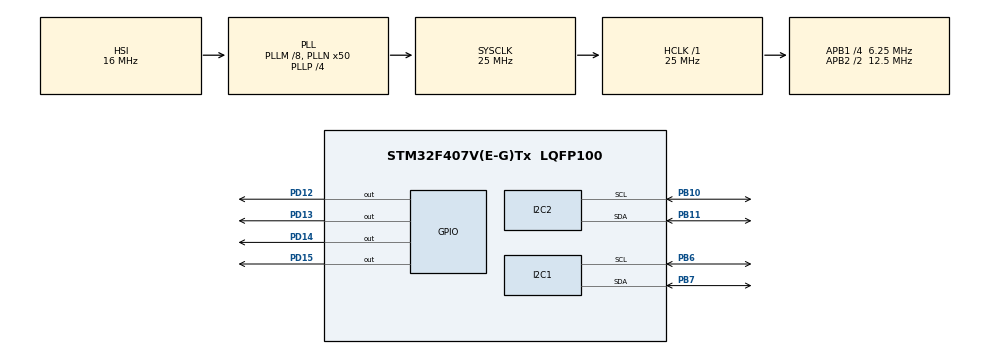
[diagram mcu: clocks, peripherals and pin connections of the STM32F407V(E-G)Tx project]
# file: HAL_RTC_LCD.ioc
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Mcu.Family=STM32F4
Mcu.Name=STM32F407V(E-G)Tx
Mcu.Package=LQFP100
NVIC.PriorityGroup=NVIC_PRIORITYGROUP_0
PB10.Mode=I2C
PB10.Signal=I2C2_SCL
PB11.Mode=I2C
PB11.Signal=I2C2_SDA
PB6.Mode=I2C
PB6.Signal=I2C1_SCL
PB7.Mode=I2C
PB7.Signal=I2C1_SDA
PD12.Signal=GPIO_Output
PD13.Signal=GPIO_Output
PD14.Signal=GPIO_Output
PD15.Signal=GPIO_Output
ProjectManager.HeapSize=0x200
ProjectManager.StackSize=0x400
ProjectManager.TargetToolchain=STM32CubeIDE
RCC.48MHZClocksFreq_Value=14285714.285714285
RCC.AHBFreq_Value=25000000
RCC.APB1CLKDivider=RCC_HCLK_DIV4
RCC.APB1Freq_Value=6250000
RCC.APB1TimFreq_Value=12500000
RCC.APB2CLKDivider=RCC_HCLK_DIV2
RCC.APB2Freq_Value=12500000
RCC.APB2TimFreq_Value=25000000
RCC.CortexFreq_Value=25000000
RCC.HCLKFreq_Value=25000000
RCC.HSE_VALUE=8000000
RCC.HSI_VALUE=16000000
RCC.LSE_VALUE=32768
RCC.PLLM=8
RCC.PLLN=50
RCC.PLLP=RCC_PLLP_DIV4
RCC.PLLQ=7
RCC.SYSCLKFreq_VALUE=25000000
RCC.SYSCLKSource=RCC_SYSCLKSOURCE_PLLCLK
RCC.VCOOutputFreq_Value=100000000
RTC.AsynchPrediv=124
RTC.Date=30
RTC.Format=RTC_FORMAT_BIN
RTC.Hours=23
RTC.Minutes=59
RTC.Month=RTC_MONTH_MARCH
RTC.Seconds=59
RTC.WeekDay=RTC_WEEKDAY_WEDNESDAY
RTC.Year=26
VP_RTC_VS_RTC_Activate.Mode=RTC_Enabled
VP_RTC_VS_RTC_Calendar.Mode=RTC_Calendar
board=STM32F407G-DISC1

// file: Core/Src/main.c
/* USER CODE BEGIN Header */
/**
  ******************************************************************************
  * @file           : main.c
  * @brief          : Main program body
  ******************************************************************************
  * @attention
  *
  * Copyright (c) 2026 STMicroelectronics.
  * All rights reserved.
  *
  * This software is licensed under terms that can be found in the LICENSE file
  * in the root directory of this software component.
  * If no LICENSE file comes with this software, it is provided AS-IS.
  *
  ******************************************************************************
  */
/* USER CODE END Header */
#include "main.h"

/* USER CODE BEGIN Includes */
#include "lcd.h"
#include <stdio.h>
#include <string.h>
/* USER CODE END Includes */

I2C_HandleTypeDef hi2c1;
I2C_HandleTypeDef hi2c2;

RTC_HandleTypeDef hrtc;

void SystemClock_Config(void);
static void MX_GPIO_Init(void);
static void MX_I2C1_Init(void);
static void MX_RTC_Init(void);
static void MX_I2C2_Init(void);

int main(void)
{

  /* MCU Configuration--------------------------------------------------------*/

  /* Reset of all peripherals, Initializes the Flash interface and the Systick. */
  HAL_Init();

  /* Configure the system clock */
  SystemClock_Config();

  /* Initialize all configured peripherals */
  MX_GPIO_Init();
  MX_I2C1_Init();
  MX_RTC_Init();
  MX_I2C2_Init();
  /* USER CODE BEGIN 2 */
  lcd_init();
  lcd_puts(LCD_LINE1, "Hello Kunal");
  char str1[20], str2[20];
  /* USER CODE END 2 */

  /* Infinite loop */
  /* USER CODE BEGIN WHILE */
  while (1)
  {
	  //Get time from rtc
	  RTC_TimeTypeDef time;
	  RTC_DateTypeDef date;
	  HAL_RTC_GetTime(&hrtc, &time, RTC_FORMAT_BIN);
	  HAL_RTC_GetDate(&hrtc, &date, RTC_FORMAT_BIN);

	  //display on lcd
	  sprintf(str1, "Date: %02d-%02d-%02d", date.Date, date.Month, date.Year);
	  sprintf(str2, "Time: %02d:%02d:%02d", time.Hours, time.Minutes, time.Seconds);

	  lcd_puts(LCD_LINE1, str1);
	  lcd_puts(LCD_LINE2, str2);
    /* USER CODE END WHILE */

  }
}

void SystemClock_Config(void)
{
  RCC_OscInitTypeDef RCC_OscInitStruct = {0};
  RCC_ClkInitTypeDef RCC_ClkInitStruct = {0};

  /** Configure the main internal regulator output voltage
  */
  __HAL_RCC_PWR_CLK_ENABLE();
  __HAL_PWR_VOLTAGESCALING_CONFIG(PWR_REGULATOR_VOLTAGE_SCALE1);

  /** Initializes the RCC Oscillators according to the specified parameters
  * in the RCC_OscInitTypeDef structure.
  */
  RCC_OscInitStruct.OscillatorType = RCC_OSCILLATORTYPE_HSI|RCC_OSCILLATORTYPE_LSI;
  RCC_OscInitStruct.HSIState = RCC_HSI_ON;
  RCC_OscInitStruct.HSICalibrationValue = RCC_HSICALIBRATION_DEFAULT;
  RCC_OscInitStruct.LSIState = RCC_LSI_ON;
  RCC_OscInitStruct.PLL.PLLState = RCC_PLL_ON;
  RCC_OscInitStruct.PLL.PLLSource = RCC_PLLSOURCE_HSI;
  RCC_OscInitStruct.PLL.PLLM = 8;
  RCC_OscInitStruct.PLL.PLLN = 50;
  RCC_OscInitStruct.PLL.PLLP = RCC_PLLP_DIV4;
  RCC_OscInitStruct.PLL.PLLQ = 7;
  if (HAL_RCC_OscConfig(&RCC_OscInitStruct) != HAL_OK)
  {
    Error_Handler();
  }

  /** Initializes the CPU, AHB and APB buses clocks
  */
  RCC_ClkInitStruct.ClockType = RCC_CLOCKTYPE_HCLK|RCC_CLOCKTYPE_SYSCLK
                              |RCC_CLOCKTYPE_PCLK1|RCC_CLOCKTYPE_PCLK2;
  RCC_ClkInitStruct.SYSCLKSource = RCC_SYSCLKSOURCE_PLLCLK;
  RCC_ClkInitStruct.AHBCLKDivider = RCC_SYSCLK_DIV1;
  RCC_ClkInitStruct.APB1CLKDivider = RCC_HCLK_DIV4;
  RCC_ClkInitStruct.APB2CLKDivider = RCC_HCLK_DIV2;

  if (HAL_RCC_ClockConfig(&RCC_ClkInitStruct, FLASH_LATENCY_0) != HAL_OK)
  {
    Error_Handler();
  }
}

static void MX_I2C1_Init(void)
{

  hi2c1.Instance = I2C1;
  hi2c1.Init.ClockSpeed = 100000;
  hi2c1.Init.DutyCycle = I2C_DUTYCYCLE_2;
  hi2c1.Init.OwnAddress1 = 0;
  hi2c1.Init.AddressingMode = I2C_ADDRESSINGMODE_7BIT;
  hi2c1.Init.DualAddressMode = I2C_DUALADDRESS_DISABLE;
  hi2c1.Init.OwnAddress2 = 0;
  hi2c1.Init.GeneralCallMode = I2C_GENERALCALL_DISABLE;
  hi2c1.Init.NoStretchMode = I2C_NOSTRETCH_DISABLE;
  if (HAL_I2C_Init(&hi2c1) != HAL_OK)
  {
    Error_Handler();
  }

}

static void MX_I2C2_Init(void)
{

  hi2c2.Instance = I2C2;
  hi2c2.Init.ClockSpeed = 100000;
  hi2c2.Init.DutyCycle = I2C_DUTYCYCLE_2;
  hi2c2.Init.OwnAddress1 = 0;
  hi2c2.Init.AddressingMode = I2C_ADDRESSINGMODE_7BIT;
  hi2c2.Init.DualAddressMode = I2C_DUALADDRESS_DISABLE;
  hi2c2.Init.OwnAddress2 = 0;
  hi2c2.Init.GeneralCallMode = I2C_GENERALCALL_DISABLE;
  hi2c2.Init.NoStretchMode = I2C_NOSTRETCH_DISABLE;
  if (HAL_I2C_Init(&hi2c2) != HAL_OK)
  {
    Error_Handler();
  }

}

static void MX_RTC_Init(void)
{

  RTC_TimeTypeDef sTime = {0};
  RTC_DateTypeDef sDate = {0};

  /** Initialize RTC Only
  */
  hrtc.Instance = RTC;
  hrtc.Init.HourFormat = RTC_HOURFORMAT_24;
  hrtc.Init.AsynchPrediv = 124;
  hrtc.Init.SynchPrediv = 255;
  hrtc.Init.OutPut = RTC_OUTPUT_DISABLE;
  hrtc.Init.OutPutPolarity = RTC_OUTPUT_POLARITY_HIGH;
  hrtc.Init.OutPutType = RTC_OUTPUT_TYPE_OPENDRAIN;
  if (HAL_RTC_Init(&hrtc) != HAL_OK)
  {
    Error_Handler();
  }

  /** Initialize RTC and set the Time and Date
  */
  sTime.Hours = 23;
  sTime.Minutes = 59;
  sTime.Seconds = 59;
  sTime.DayLightSaving = RTC_DAYLIGHTSAVING_NONE;
  sTime.StoreOperation = RTC_STOREOPERATION_RESET;
  if (HAL_RTC_SetTime(&hrtc, &sTime, RTC_FORMAT_BIN) != HAL_OK)
  {
    Error_Handler();
  }
  sDate.WeekDay = RTC_WEEKDAY_WEDNESDAY;
  sDate.Month = RTC_MONTH_MARCH;
  sDate.Date = 30;
  sDate.Year = 26;

  if (HAL_RTC_SetDate(&hrtc, &sDate, RTC_FORMAT_BIN) != HAL_OK)
  {
    Error_Handler();
  }

}

static void MX_GPIO_Init(void)
{
  GPIO_InitTypeDef GPIO_InitStruct = {0};

  /* GPIO Ports Clock Enable */
  __HAL_RCC_GPIOB_CLK_ENABLE();
  __HAL_RCC_GPIOD_CLK_ENABLE();

  /*Configure GPIO pin Output Level */
  HAL_GPIO_WritePin(GPIOD, GPIO_PIN_12|GPIO_PIN_13|GPIO_PIN_14|GPIO_PIN_15, GPIO_PIN_RESET);

  /*Configure GPIO pins : PD12 PD13 PD14 PD15 */
  GPIO_InitStruct.Pin = GPIO_PIN_12|GPIO_PIN_13|GPIO_PIN_14|GPIO_PIN_15;
  GPIO_InitStruct.Mode = GPIO_MODE_OUTPUT_PP;
  GPIO_InitStruct.Pull = GPIO_NOPULL;
  GPIO_InitStruct.Speed = GPIO_SPEED_FREQ_LOW;
  HAL_GPIO_Init(GPIOD, &GPIO_InitStruct);

}

void Error_Handler(void)
{
  __disable_irq();
  while (1)
  {
  }
}
